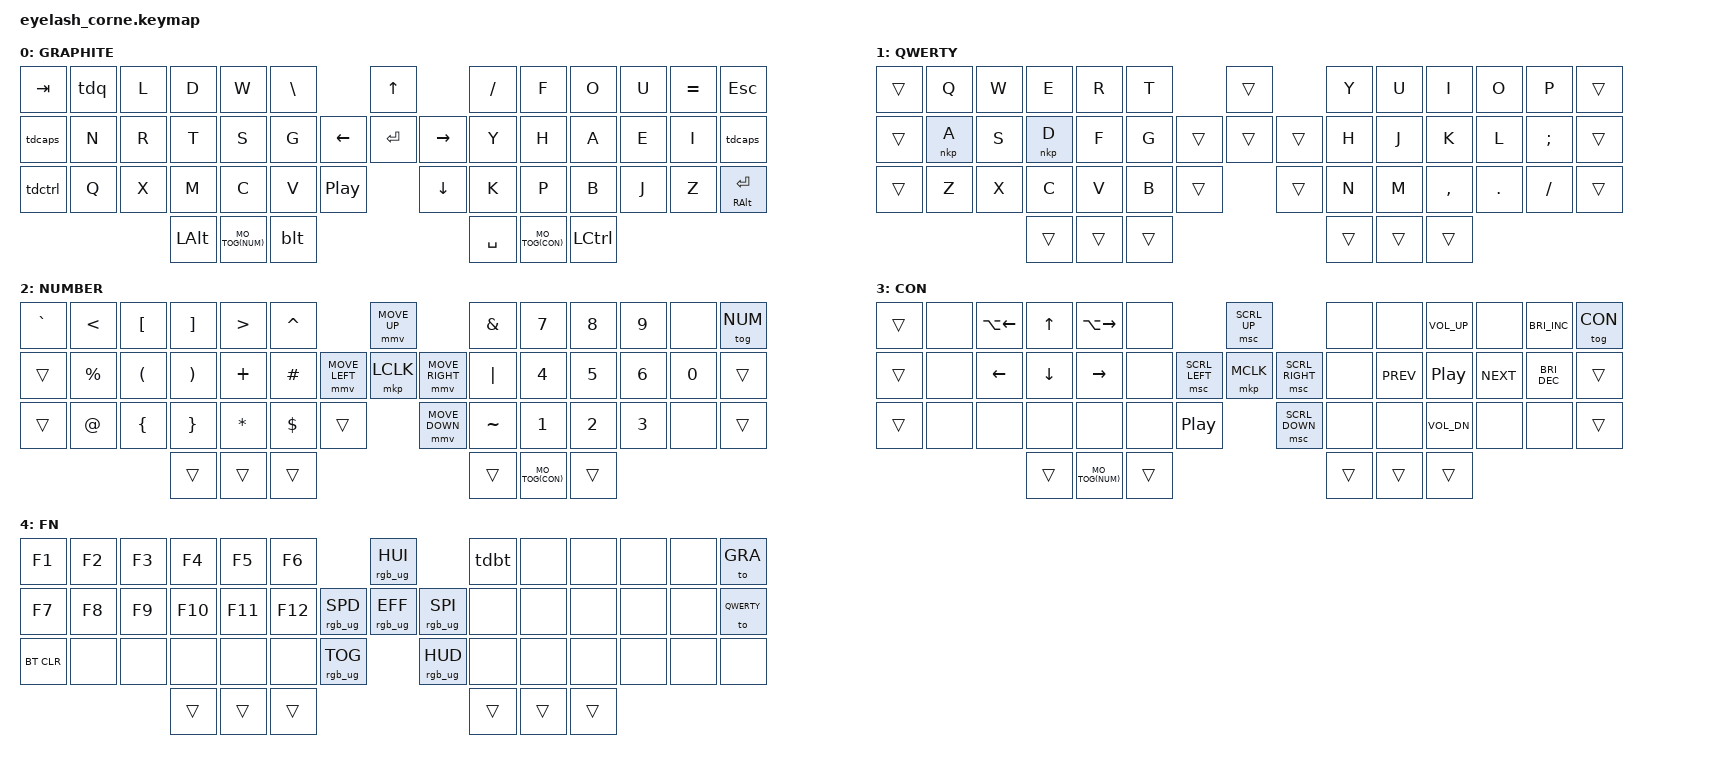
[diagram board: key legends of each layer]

#define ZMK_POINTING_DEFAULT_MOVE_VAL 800  // 600
#define ZMK_POINTING_DEFAULT_SCRL_VAL 25   // 10

#include <input/processors.dtsi>
#include <zephyr/dt-bindings/input/input-event-codes.h>
#include <behaviors.dtsi>
#include <behaviors/non_overlap.dtsi>
#include <dt-bindings/zmk/bt.h>
#include <dt-bindings/zmk/keys.h>
#include <dt-bindings/zmk/outputs.h>
#include <dt-bindings/zmk/pointing.h>
#include <dt-bindings/zmk/rgb.h>
#include <dt-bindings/zmk/rgb.h>

//======definitions========//
#define GRA 0
#define QWERTY 1
#define NUM 2
#define CON 3
#define FN 4

#define MO_TOG(layer) &mo_tog layer layer
#define AA(keycode) &ht_tp RA(keycode) keycode
#define CTRL(keycode) &ht_tp LC(keycode) LG(keycode)

//=========================//=========================/ Version: 4 /=========================//=========================//

/ {
    conditional_layers {
        compatible = "zmk,conditional-layers";
        funcion_layer {
            if-layers = <2 3>;
            then-layer = <4>;
        };
    };
};

&mt {
    flavor = "tap-preferred";
    tapping-term-ms = <240>;
};

&mmv_input_listener { input-processors = <&zip_xy_scaler 2 1>; };

&msc_input_listener { input-processors = <&zip_scroll_scaler 2 1>; };

&msc {
    acceleration-exponent = <1>;      // 0
    time-to-max-speed-ms = <100>;       // 300
    delay-ms = <0>;                   // 0
};

&mmv {
    time-to-max-speed-ms = <500>;
    acceleration-exponent = <1>;
    trigger-period-ms = <16>;
};

&soft_off { hold-time-ms = <2000>; };

//==================== COMBOS ====================//
/ {
    combos {
        compatible = "zmk,combos";

        softoff {
            bindings = <&soft_off>;
            key-positions = <1 15 29>;
            layers = <0 2 3 4>;
        };

        combo_dot {
            timeout-ms = <50>;
            key-positions = <16 17>;
            bindings = <&kp DOT>;
            layers = <0 2 3 4>;
        };
        combo_comma {
            timeout-ms = <50>;
            key-positions = <23 24>;
            bindings = <&kp COMMA>;
            layers = <0 2 3 4>;
        };
        combo_colon {
            timeout-ms = <50>;
            key-positions = <3 4>;
            bindings = <&kp COLON>;
            layers = <0 2 3 4>;
        };
        combo_semicolon {
            timeout-ms = <50>;
            key-positions = <8 9>;
            bindings = <&kp SEMI>;
            layers = <0 2 3 4>;
        };
        combo_qmark {
            timeout-ms = <50>;
            key-positions = <9 10>;
            bindings = <&kp QMARK>;
            layers = <0 2 3 4>;
        };
        combo_exmark {
            timeout-ms = <50>;
            key-positions = <24 25>;
            bindings = <&kp EXCL>;
            layers = <0 2 3 4>;
        };
        combo_minus {
            timeout-ms = <50>;
            key-positions = <15 16>;
            bindings = <&kp MINUS>;
            layers = <0 2 3 4>;
        };
        combo_underscore {
            timeout-ms = <50>;
            key-positions = <30 31>;
            bindings = <&kp UNDER>;
            layers = <0 2 3 4>;
        };
        combo_cut {
            timeout-ms = <50>;
            key-positions = <36 37>;
            bindings = <CTRL(X)>;
            layers = <0 2 3 4>;
        };
        combo_copy {
            timeout-ms = <50>;
            key-positions = <37 38>;
            bindings = <CTRL(C)>;
            layers = <0 2 3 4>;
        };
        combo_paste {
            timeout-ms = <50>;
            key-positions = <38 39>;
            bindings = <CTRL(V)>;
            layers = <0 2 3 4>;
        };
        combo_back {
            timeout-ms = <50>;
            key-positions = <0 1>;
            bindings = <CTRL(Z)>;
            layers = <0 2 3 4>;
        };
        combo_forward{
            timeout-ms = <50>;
            key-positions = <1 2>;
            bindings = <CTRL(LS(Z))>;
            layers = <0 2 3 4>;
        };
    };
};

//================= MACROS =====================//
/ {
    macros {
        swch_mac: swch_mac {
            compatible = "zmk,behavior-macro";
            #binding-cells = <0>;
            bindings
                = <&macro_tap &bt BT_SEL 0>
                , <&macro_tap &to GRA>
                ;
        };
    };
};

/ {
    behaviors {
//==================== TAP DANCES ====================//
        tdq: tap_dance_quotation {
                compatible = "zmk,behavior-tap-dance";
                #binding-cells = <0>;
                tapping-term-ms = <300>;
                bindings = <&kp SQT>, <&kp DQT>;
        };

        tdctrl: tap_dance_command_control {
                compatible = "zmk,behavior-tap-dance";
                #binding-cells = <0>;
                tapping-term-ms = <250>;
                bindings = <&kp LGUI>, <&kp LCTRL>, <&kp LG(LCTRL)>;
        };

        tdcaps: tap_dance_shift_caps {
                compatible = "zmk,behavior-tap-dance";
                #binding-cells = <0>;
                tapping-term-ms = <300>;
                bindings = <&kp LSHFT>, <&kp CAPS>;
        };
        
        tdbt: tap_dance_bluetooth {
                compatible = "zmk,behavior-tap-dance";
                #binding-cells = <0>;
                tapping-term-ms = <300>;
                bindings = <&bt BT_SEL 0>, <&bt BT_SEL 1>, <&bt BT_SEL 2>, <&bt BT_SEL 3>, <&bt BT_SEL 4>;
        };

//==================== HOLD TAPS ====================//
        mo_tog: behavior_mo_tog {
                compatible = "zmk,behavior-hold-tap";
                #binding-cells = <2>;
                flavor = "hold-preferred";
                tapping-term-ms = <200>;
                bindings = <&mo>, <&tog>;
        };

        ht_tp: behavior_tap_preferred {
                compatible = "zmk,behavior-hold-tap";
                #binding-cells = <2>;
                tapping_term_ms = <240>;
                quick_tap_ms = <0>;
                flavor = "tap-preferred";
                bindings = <&kp>, <&kp>;
        };

//==================== MOD MORPH ====================//
        blt: backspace_delete {
                compatible = "zmk,behavior-mod-morph";
                #binding-cells = <0>;
                bindings = <&kp BSPC>, <&kp DEL>;
                mods = <(MOD_LSFT|MOD_RSFT)>;
        };
    };

//==================== ENCODERS ====================//
    rgb_encoder: rgb_encoder {
        compatible = "zmk,behavior-sensor-rotate";
        #sensor-binding-cells = <0>;
        bindings = <&rgb_ug RGB_BRI>, <&rgb_ug RGB_BRD>;
    };

    scroll_encoder: scroll_encoder {
        compatible = "zmk,behavior-sensor-rotate";
        #sensor-binding-cells = <0>;
        bindings = <&msc SCRL_DOWN>, <&msc SCRL_UP>;

        tap-ms = <100>;
    };

//============================== KEYMAP ==============================//
    keymap {
        compatible = "zmk,keymap";

        default_layer {
            display-name = "GRAPHITE";
            bindings = <

&kp TAB    &tdq      &kp L     &kp D     &kp W        &kp BSLH                            &kp UP                &kp FSLH  &kp F         &kp O     &kp U    &kp EQUAL &kp ESC
&tdcaps    &kp N     &kp R     &kp T     &kp S        &kp G                      &kp LEFT &kp ENTER  &kp RIGHT  &kp Y     &kp H         &kp A     &kp E    &kp I     &tdcaps
&tdctrl    &kp Q     &kp X     &kp M     &kp C        &kp V            &kp C_PP           &kp DOWN              &kp K     &kp P         &kp B     &kp J    &kp Z     &mt RALT RET
                               &kp LALT  MO_TOG(NUM)  &blt                                              &kp SPACE    MO_TOG(CON)   &kp LCTRL

            >;

            sensor-bindings = <&inc_dec_kp C_VOLUME_UP C_VOLUME_DOWN>;
        };

        qwerty_layer {
            display-name = "QWERTY";
            bindings = <
&trans    &kp Q    &kp W     &kp E     &kp R      &kp T              &trans         &kp Y     &kp U     &kp I      &kp O    &kp P     &trans
&trans    &nkp A   &kp S     &nkp D    &kp F      &kp G       &trans &trans &trans  &kp H     &kp J     &kp K      &kp L    &kp SEMI  &trans
&trans    &kp Z    &kp X     &kp C     &kp V      &kp B    &trans    &trans         &kp N     &kp M     &kp COMMA  &kp DOT  &kp FSLH  &trans
                             &trans    &trans     &trans                            &trans    &trans    &trans
            >;

            sensor-bindings = <&inc_dec_kp C_VOLUME_UP C_VOLUME_DOWN>;
        };

        number_layer {
            display-name = "NUMBER";
            bindings = <
&kp GRAVE &kp LT     &kp LBKT  &kp RBKT  &kp GT    &kp CARET                        &mmv MOVE_UP                &kp AMPS   &kp N7        &kp N8  &kp N9  &none   &tog NUM
&trans    &kp PRCNT  &kp LPAR  &kp RPAR  &kp PLUS  &kp HASH          &mmv MOVE_LEFT &mkp LCLK  &mmv MOVE_RIGHT  &kp PIPE   &kp N4        &kp N5  &kp N6  &kp N0  &trans
&trans    &kp AT     &kp LBRC  &kp RBRC  &kp STAR  &kp DLLR   &trans                &mmv MOVE_DOWN              &kp TILDE  &kp N1        &kp N2  &kp N3  &none   &trans
                               &trans    &trans    &trans                                                       &trans     MO_TOG(CON)  &trans
            >;

            sensor-bindings = <&scroll_encoder>;
        };

        control_layer {
            display-name = "CON";
            bindings = <
   &trans  &none  &kp LA(LEFT)  &kp UP    &kp LA(RIGHT)  &none                                &msc SCRL_UP                    &none   &none       &kp C_VOL_UP  &none       &kp C_BRI_INC &tog CON
   &trans  &none  &kp LEFT      &kp DOWN  &kp RIGHT      &none                &msc SCRL_LEFT  &mkp MCLK     &msc SCRL_RIGHT   &none   &kp C_PREV  &kp C_PP      &kp C_NEXT  &kp C_BRI_DEC &trans
   &trans  &none  &none         &none     &none          &none     &kp C_PP                   &msc SCRL_DOWN                  &none   &none       &kp C_VOL_DN  &none       &none         &trans
                                &trans    MO_TOG(NUM)    &trans                                                               &trans  &trans       &trans
            >;

            sensor-bindings = <&scroll_encoder>;
        };

        function_layer {
            display-name = "FN";
            bindings = <
   &kp F1      &kp F2  &kp F3  &kp F4   &kp F5   &kp F6                                 &rgb_ug RGB_HUI                    &tdbt   &none  &none  &none  &none  &to GRA
   &kp F7      &kp F8  &kp F9  &kp F10  &kp F11  &kp F12                &rgb_ug RGB_SPD &rgb_ug RGB_EFF &rgb_ug RGB_SPI    &none   &none  &none  &none  &none  &to QWERTY
   &bt BT_CLR  &none   &none   &none    &none    &none     &rgb_ug RGB_TOG              &rgb_ug RGB_HUD                    &none   &none  &none  &none  &none  &none
                               &trans   &trans   &trans                                                                    &trans  &trans  &trans
            >;

            sensor-bindings = <&rgb_encoder>;
        };
    };
};
